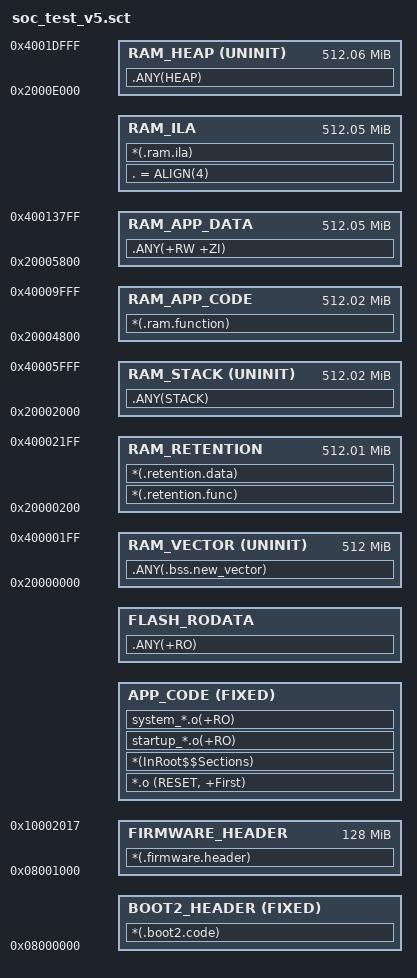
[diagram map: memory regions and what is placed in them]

LOAD_BOOT2_CODE 0x8000000 0x8001000
{
    BOOT2_HEADER +0 FIXED
    {
        *(.boot2.code)
    }
}

LOAD_APP 0x8001000 0x8040000
{

    FIRMWARE_HEADER 0x8001000 0x8001018
    {
        *(.firmware.header)
    }

    APP_CODE +0 FIXED
    {
        *.o (RESET, +First)
        *(InRoot$$Sections)
        startup_*.o(+RO)
        system_*.o(+RO)
    }

    FLASH_RODATA +0
    {
        .ANY(+RO)
    }

    ; TODO: connot single section, keil flash program will faild
    RAM_VECTOR 0x20000000 UNINIT 0x20000200
    {
        .ANY(.bss.new_vector)
    }

    RAM_RETENTION 0x20000200 0x20002000
    {
        *(.retention.func)
        *(.retention.data)
    }

    RAM_APP_CODE 0x20004800 0x20005800
    {
        *(.ram.function)
    }

    RAM_APP_DATA 0x20005800 0x2000E000
    {
        .ANY(+RW +ZI)
    }

    RAM_ILA ImageLimit(RAM_APP_DATA) 0x2000E000
    {
        . = ALIGN(4);
        *(.ram.ila)
    }

    RAM_HEAP 0x2000E000 UNINIT 0x20010000
    {
        .ANY(HEAP)
    }

    RAM_STACK 0x20002000 UNINIT 0x20004000
    {
        .ANY(STACK)
    }
}
